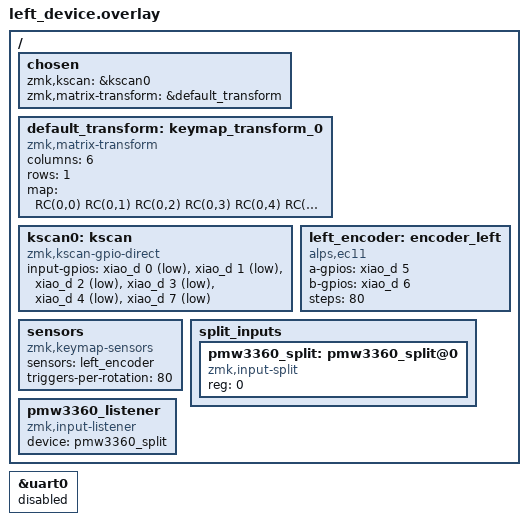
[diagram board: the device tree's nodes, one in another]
/*
 * Copyright (c) 2026 The ZMK Contributors
 * SPDX-License-Identifier: MIT
 */

#include <dt-bindings/zmk/matrix_transform.h>

/ {
    chosen {
        zmk,kscan = &kscan0;
        zmk,matrix-transform = &default_transform;
    };

    default_transform: keymap_transform_0 {
        compatible = "zmk,matrix-transform";
        columns = <6>;
        rows = <1>;
        map = <
            RC(0,0) RC(0,1) RC(0,2) RC(0,3) RC(0,4) RC(0,5)
        >;
    };

    kscan0: kscan {
        compatible = "zmk,kscan-gpio-direct";
        input-gpios
            = <&xiao_d 0 (GPIO_ACTIVE_LOW | GPIO_PULL_UP)> // SW2 (KEY_1)
            , <&xiao_d 1 (GPIO_ACTIVE_LOW | GPIO_PULL_UP)> // SW3 (KEY_2)
            , <&xiao_d 2 (GPIO_ACTIVE_LOW | GPIO_PULL_UP)> // SW4 (KEY_3)
            , <&xiao_d 3 (GPIO_ACTIVE_LOW | GPIO_PULL_UP)> // SW5 (KEY_4)
            , <&xiao_d 4 (GPIO_ACTIVE_LOW | GPIO_PULL_UP)> // SW6 (KEY_5)
            , <&xiao_d 7 (GPIO_ACTIVE_LOW | GPIO_PULL_UP)> // SW1 (ENC_SW)
            ;
    };

    left_encoder: encoder_left {
        compatible = "alps,ec11";
        a-gpios = <&xiao_d 5 (GPIO_ACTIVE_HIGH | GPIO_PULL_UP)>;
        b-gpios = <&xiao_d 6 (GPIO_ACTIVE_HIGH | GPIO_PULL_UP)>;
        steps = <80>;
        status = "okay";
    };

    sensors: sensors {
        compatible = "zmk,keymap-sensors";
        sensors = <&left_encoder>;
        triggers-per-rotation = <80>;
    };

    split_inputs {
        #address-cells = <1>;
        #size-cells = <0>;

        pmw3360_split: pmw3360_split@0 {
            compatible = "zmk,input-split";
            reg = <0>;
        };
    };

    pmw3360_listener: pmw3360_listener {
        compatible = "zmk,input-listener";
        device = <&pmw3360_split>;
    };
};

/* Disable UART0 so D6 (TX) and D7 (RX) can be used as GPIO pins (Encoder B and Push switch) */
&uart0 {
    status = "disabled";
};
